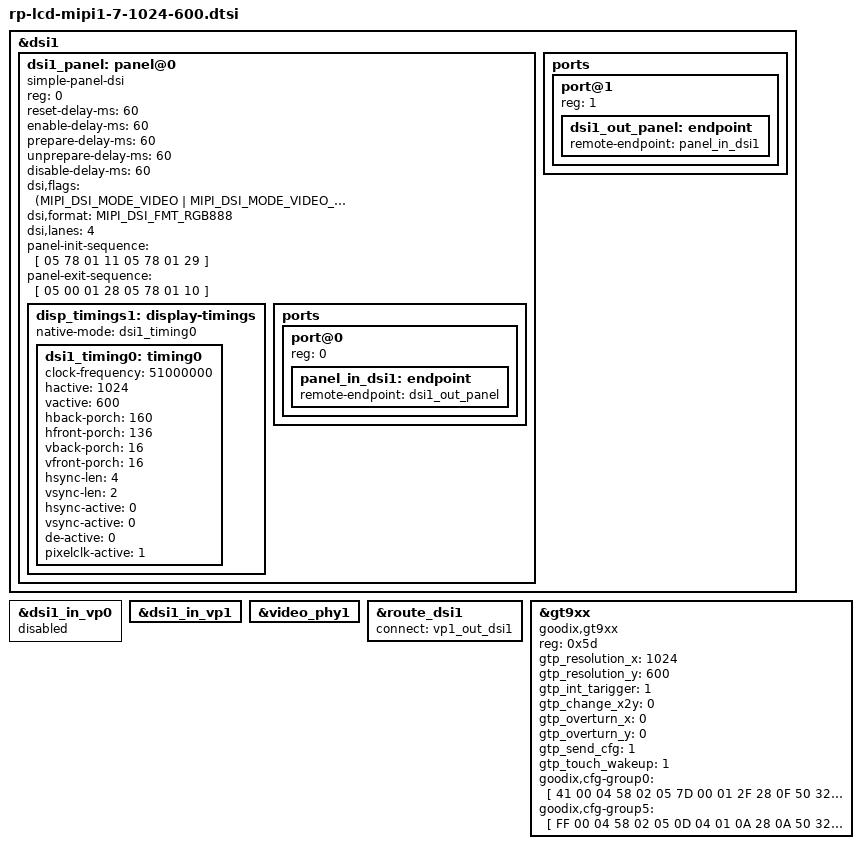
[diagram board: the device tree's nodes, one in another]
#include "rp-lcd-hdmi.dtsi"
#define RP_SINGLE_LCD
#define RP_MIPI1_USED




&dsi1 {
	status = "okay";
	//rockchip,lane-rate = <480>;
	dsi1_panel: panel@0 {
		status = "okay";
		compatible = "simple-panel-dsi";
		reg = <0>;
		reset-delay-ms = <60>;
		enable-delay-ms = <60>;
		prepare-delay-ms = <60>;
		unprepare-delay-ms = <60>;
		disable-delay-ms = <60>;
		dsi,flags = <(MIPI_DSI_MODE_VIDEO | MIPI_DSI_MODE_VIDEO_BURST |
			MIPI_DSI_MODE_LPM | MIPI_DSI_MODE_EOT_PACKET)>;
		dsi,format = <MIPI_DSI_FMT_RGB888>;
		dsi,lanes  = <4>;
		
		/**
		 * power-supply = <>;
		 * reset-gpios = <>;
		 *
		 * lcd reset pin and power supply
		 * please refer to ***-lcd-gpio.dtsi
		 * that included in main dts.
		 */
		
		panel-init-sequence = [
			05 78 01 11
			05 78 01 29
		];
		
		panel-exit-sequence = [
			05 00 01 28
			05 78 01 10
		];

		disp_timings1: display-timings {
			native-mode = <&dsi1_timing0>;
			dsi1_timing0: timing0 {
				clock-frequency = <51000000>;
				hactive = <1024>;
				vactive = <600>;
				hback-porch = <160>;
				hfront-porch = <136>;
				vback-porch = <16>;
				vfront-porch = <16>;
				hsync-len = <4>;
				vsync-len = <2>;
				hsync-active = <0>;
				vsync-active = <0>;
				de-active = <0>;
				pixelclk-active = <1>;
			};
		};

		ports {
			#address-cells = <1>;
			#size-cells = <0>;

			port@0 {
				reg = <0>;
				panel_in_dsi1: endpoint {
					remote-endpoint = <&dsi1_out_panel>;
				};
			};
		};
	};

	ports {
		#address-cells = <1>;
		#size-cells = <0>;

		port@1 {
			reg = <1>;
			dsi1_out_panel: endpoint {
				remote-endpoint = <&panel_in_dsi1>;
			};
		};
	};
};



&dsi1_in_vp0 {
	status = "disabled";
};

&dsi1_in_vp1 {
	status = "okay";
};

&video_phy1{
	status = "okay";
};

&route_dsi1 {
	status = "okay";
	connect = <&vp1_out_dsi1>;
};



&gt9xx {
	status = "okay";
	compatible = "goodix,gt9xx";
	reg = <0x5d>;
	gtp_resolution_x = <1024>;
	gtp_resolution_y = <600>;
	gtp_int_tarigger = <1>;
	gtp_change_x2y = <0>;
	gtp_overturn_x = <0>;
	gtp_overturn_y = <0>;
	gtp_send_cfg = <1>;
	gtp_touch_wakeup = <1>;

	/**
	 * goodix_rst_gpio = <>;
	 * goodix_irq_gpio = <>;
	 *
	 * touch panel interrupt and reset pin
	 * please refer to ***-lcd-gpio.dtsi
	 * that included in main dts.
	 */
	
	goodix,cfg-group0 = [   //old touch
		41 00 04 58 02 05 7D 00 01 2F 28 
		0F 50 32 03 05 00 00 00 00 00 00 
		00 18 1A 1E 14 89 0D 0C 2C 2A 0C 
		08 00 00 00 82 03 1D 0A 32 05 0A 
		32 00 00 00 00 00 0B 1E 50 94 E5 
		02 08 00 00 04 A7 21 00 8B 28 00 
		73 31 00 62 3B 00 52 48 00 52 00 
		00 00 00 00 00 00 00 00 00 00 00 
		00 00 00 00 00 00 00 00 00 00 00 
		00 00 00 00 00 00 00 00 32 50 00 
		00 00 1C 1A 18 16 14 12 10 0E 0C 
		0A 08 06 04 02 00 00 00 00 00 00
		00 00 00 00 00 00 00 00 00 00 2A
		29 28 26 24 22 21 20 1F 1E 1D 18
		16 14 13 12 10 0F 0C 0A 08 06 FF
		FF FF FF 00 00 00 00 00 00 00 00
		00 00 00 00 00 00 00 00 3B 01
	];
	goodix,cfg-group5 = [   //new touch
		FF 00 04 58 02 05 0D 04 01
		0A 28 0A 50 32 03 05 00 00
		00 00 00 00 08 00 00 00 00
		8B 2B 0E 30 32 0F 0A 00 00
		00 83 02 1D 00 00 00 00 00
		03 03 32 00 00 00 24 60 94
		C0 02 00 00 00 04 93 27 00
		80 30 00 70 3B 00 65 47 00
		5C 57 00 5C 00 00 00 00 00
		00 00 00 00 00 00 00 00 00
		00 00 00 00 00 00 00 00 00
		00 00 00 00 00 00 00 00 00
		00 00 00 00 1C 1A 18 16 14
		12 10 0E 0C 0A 08 06 04 02
		00 00 00 00 00 00 00 00 00
		00 00 00 00 00 00 00 26 24
		22 21 20 1F 1E 1D 1C 18 16
		13 12 10 0F 0C 0A 08 06 04
		02 00 FF FF FF FF 00 00 00
		00 00 00 00 00 00 00 00 00
		00 00 00 00 6A 01
	];
};

